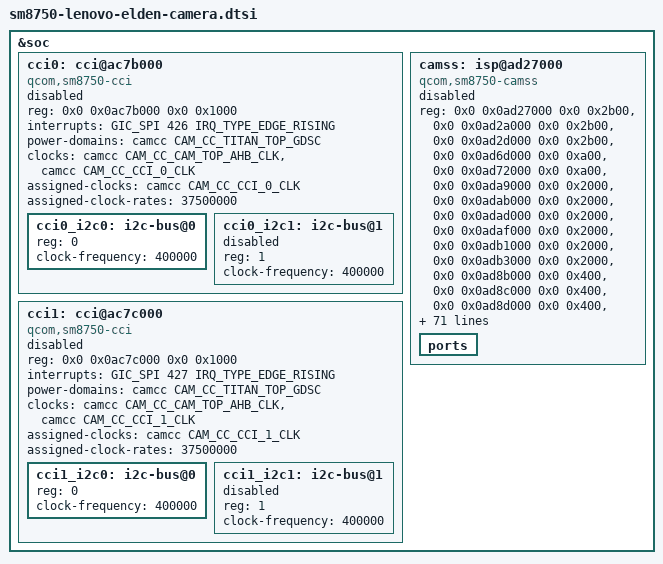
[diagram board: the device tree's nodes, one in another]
// SPDX-License-Identifier: BSD-3-Clause
/*
 * Copyright (c) 2024 Qualcomm Innovation Center, Inc. All rights reserved.
 *
 * CCI / CAMSS control nodes for the Lenovo Legion Y700 Gen4 (TB322FC).
 * Copied verbatim from sm8750.dtsi in h0cheung/tb322fc-linux-kernel,
 * commit 6f97250ead155fc3b980856323e99a4623dae73d, lines 3072-3309:
 *   cci0: cci@ac7b000, cci1: cci@ac7c000, camss: isp@ad27000.
 * Only leading indentation is normalized by one tab; all node contents are
 * unchanged. No other SoC delta is imported. These nodes supply the board
 * label references &camss, &cci0, &cci0_i2c0, &cci1 and &cci1_i2c0 used by
 * sm8750-lenovo-elden.dts; their clocks, interrupts and other phandles come
 * from the current upstream base. This file declares no driver and provides
 * no camera support.
 */

&soc {
	cci0: cci@ac7b000 {
		compatible = "qcom,sm8750-cci", "qcom,msm8996-cci";
		reg = <0x0 0x0ac7b000 0x0 0x1000>;
		interrupts = <GIC_SPI 426 IRQ_TYPE_EDGE_RISING>;
		power-domains = <&camcc CAM_CC_TITAN_TOP_GDSC>;
		clocks = <&camcc CAM_CC_CAM_TOP_AHB_CLK>,
			 <&camcc CAM_CC_CCI_0_CLK>;
		clock-names = "ahb", "cci";
		assigned-clocks = <&camcc CAM_CC_CCI_0_CLK>;
		assigned-clock-rates = <37500000>;
		status = "disabled";
		#address-cells = <1>;
		#size-cells = <0>;

		cci0_i2c0: i2c-bus@0 {
			reg = <0>;
			clock-frequency = <400000>;
			#address-cells = <1>;
			#size-cells = <0>;
		};

		cci0_i2c1: i2c-bus@1 {
			status = "disabled";
			reg = <1>;
			clock-frequency = <400000>;
			#address-cells = <1>;
			#size-cells = <0>;
		};
	};

	cci1: cci@ac7c000 {
		compatible = "qcom,sm8750-cci", "qcom,msm8996-cci";
		reg = <0x0 0x0ac7c000 0x0 0x1000>;
		interrupts = <GIC_SPI 427 IRQ_TYPE_EDGE_RISING>;
		power-domains = <&camcc CAM_CC_TITAN_TOP_GDSC>;
		clocks = <&camcc CAM_CC_CAM_TOP_AHB_CLK>,
			 <&camcc CAM_CC_CCI_1_CLK>;
		clock-names = "ahb", "cci";
		assigned-clocks = <&camcc CAM_CC_CCI_1_CLK>;
		assigned-clock-rates = <37500000>;
		status = "disabled";
		#address-cells = <1>;
		#size-cells = <0>;

		cci1_i2c0: i2c-bus@0 {
			reg = <0>;
			clock-frequency = <400000>;
			#address-cells = <1>;
			#size-cells = <0>;
		};

		cci1_i2c1: i2c-bus@1 {
			status = "disabled";
			reg = <1>;
			clock-frequency = <400000>;
			#address-cells = <1>;
			#size-cells = <0>;
		};
	};

	camss: isp@ad27000 {
		compatible = "qcom,sm8750-camss";

		reg = <0x0 0x0ad27000 0x0 0x2b00>,
		      <0x0 0x0ad2a000 0x0 0x2b00>,
		      <0x0 0x0ad2d000 0x0 0x2b00>,
		      <0x0 0x0ad6d000 0x0 0xa00>,
		      <0x0 0x0ad72000 0x0 0xa00>,
		      <0x0 0x0ada9000 0x0 0x2000>,
		      <0x0 0x0adab000 0x0 0x2000>,
		      <0x0 0x0adad000 0x0 0x2000>,
		      <0x0 0x0adaf000 0x0 0x2000>,
		      <0x0 0x0adb1000 0x0 0x2000>,
		      <0x0 0x0adb3000 0x0 0x2000>,
		      <0x0 0x0ad8b000 0x0 0x400>,
		      <0x0 0x0ad8c000 0x0 0x400>,
		      <0x0 0x0ad8d000 0x0 0x400>,
		      <0x0 0x0ac86000 0x0 0x10000>,
		      <0x0 0x0ac96000 0x0 0x10000>,
		      <0x0 0x0aca6000 0x0 0x10000>,
		      <0x0 0x0ad6e000 0x0 0x3000>,
		      <0x0 0x0ad73000 0x0 0x3000>;
		reg-names = "csid0",
			    "csid1",
			    "csid2",
			    "csid_lite0",
			    "csid_lite1",
			    "csiphy0",
			    "csiphy1",
			    "csiphy2",
			    "csiphy3",
			    "csiphy4",
			    "csiphy5",
			    "csitpg0",
			    "csitpg1",
			    "csitpg2",
			    "vfe0",
			    "vfe1",
			    "vfe2",
			    "vfe_lite0",
			    "vfe_lite1";

		clocks = <&camcc CAM_CC_CAMNOC_NRT_AXI_CLK>,
			 <&camcc CAM_CC_CAMNOC_RT_AXI_CLK>,
			 <&camcc CAM_CC_CAM_TOP_AHB_CLK>,
			 <&camcc CAM_CC_CAM_TOP_FAST_AHB_CLK>,
			 <&camcc CAM_CC_CAMNOC_RT_TFE_0_MAIN_CLK>,
			 <&camcc CAM_CC_CAMNOC_RT_TFE_1_MAIN_CLK>,
			 <&camcc CAM_CC_CAMNOC_RT_TFE_2_MAIN_CLK>,
			 <&camcc CAM_CC_CAMNOC_RT_IFE_LITE_CLK>,
			 <&camcc CAM_CC_CSID_CLK>,
			 <&camcc CAM_CC_CSID_CSIPHY_RX_CLK>,
			 <&camcc CAM_CC_CSIPHY0_CLK>,
			 <&camcc CAM_CC_CSI0PHYTIMER_CLK>,
			 <&camcc CAM_CC_CSIPHY1_CLK>,
			 <&camcc CAM_CC_CSI1PHYTIMER_CLK>,
			 <&camcc CAM_CC_CSIPHY2_CLK>,
			 <&camcc CAM_CC_CSI2PHYTIMER_CLK>,
			 <&camcc CAM_CC_CSIPHY3_CLK>,
			 <&camcc CAM_CC_CSI3PHYTIMER_CLK>,
			 <&camcc CAM_CC_CSIPHY4_CLK>,
			 <&camcc CAM_CC_CSI4PHYTIMER_CLK>,
			 <&camcc CAM_CC_CSIPHY5_CLK>,
			 <&camcc CAM_CC_CSI5PHYTIMER_CLK>,
			 <&gcc GCC_CAMERA_HF_AXI_CLK>,
			 <&gcc GCC_CAMERA_SF_AXI_CLK>,
			 <&camcc CAM_CC_TFE_0_MAIN_CLK>,
			 <&camcc CAM_CC_TFE_0_MAIN_FAST_AHB_CLK>,
			 <&camcc CAM_CC_TFE_1_MAIN_CLK>,
			 <&camcc CAM_CC_TFE_1_MAIN_FAST_AHB_CLK>,
			 <&camcc CAM_CC_TFE_2_MAIN_CLK>,
			 <&camcc CAM_CC_TFE_2_MAIN_FAST_AHB_CLK>,
			 <&camcc CAM_CC_IFE_LITE_CLK>,
			 <&camcc CAM_CC_IFE_LITE_AHB_CLK>,
			 <&camcc CAM_CC_IFE_LITE_CPHY_RX_CLK>,
			 <&camcc CAM_CC_IFE_LITE_CSID_CLK>,
			 <&camcc CAM_CC_QDSS_DEBUG_XO_CLK>;
		clock-names = "camnoc_nrt_axi",
			      "camnoc_rt_axi",
			      "cpas_ahb",
			      "cpas_fast_ahb",
			      "cpas_vfe0",
			      "cpas_vfe1",
			      "cpas_vfe2",
			      "cpas_vfe_lite",
			      "csid",
			      "csid_csiphy_rx",
			      "csiphy0",
			      "csiphy0_timer",
			      "csiphy1",
			      "csiphy1_timer",
			      "csiphy2",
			      "csiphy2_timer",
			      "csiphy3",
			      "csiphy3_timer",
			      "csiphy4",
			      "csiphy4_timer",
			      "csiphy5",
			      "csiphy5_timer",
			      "gcc_axi_hf",
			      "gcc_axi_sf",
			      "vfe0",
			      "vfe0_fast_ahb",
			      "vfe1",
			      "vfe1_fast_ahb",
			      "vfe2",
			      "vfe2_fast_ahb",
			      "vfe_lite",
			      "vfe_lite_ahb",
			      "vfe_lite_cphy_rx",
			      "vfe_lite_csid",
			      "qdss_debug_xo";

		interrupts = <GIC_SPI 601 IRQ_TYPE_EDGE_RISING>,
			     <GIC_SPI 603 IRQ_TYPE_EDGE_RISING>,
			     <GIC_SPI 431 IRQ_TYPE_EDGE_RISING>,
			     <GIC_SPI 605 IRQ_TYPE_EDGE_RISING>,
			     <GIC_SPI 376 IRQ_TYPE_EDGE_RISING>,
			     <GIC_SPI 477 IRQ_TYPE_EDGE_RISING>,
			     <GIC_SPI 478 IRQ_TYPE_EDGE_RISING>,
			     <GIC_SPI 479 IRQ_TYPE_EDGE_RISING>,
			     <GIC_SPI 448 IRQ_TYPE_EDGE_RISING>,
			     <GIC_SPI 122 IRQ_TYPE_EDGE_RISING>,
			     <GIC_SPI 89 IRQ_TYPE_EDGE_RISING>,
			     <GIC_SPI 433 IRQ_TYPE_EDGE_RISING>,
			     <GIC_SPI 436 IRQ_TYPE_EDGE_RISING>,
			     <GIC_SPI 457 IRQ_TYPE_EDGE_RISING>,
			     <GIC_SPI 606 IRQ_TYPE_EDGE_RISING>,
			     <GIC_SPI 377 IRQ_TYPE_EDGE_RISING>;
		interrupt-names = "csid0",
				  "csid1",
				  "csid2",
				  "csid_lite0",
				  "csid_lite1",
				  "csiphy0",
				  "csiphy1",
				  "csiphy2",
				  "csiphy3",
				  "csiphy4",
				  "csiphy5",
				  "vfe0",
				  "vfe1",
				  "vfe2",
				  "vfe_lite0",
				  "vfe_lite1";

		interconnects = <&gem_noc MASTER_APPSS_PROC QCOM_ICC_TAG_ACTIVE_ONLY
				 &config_noc SLAVE_CAMERA_CFG QCOM_ICC_TAG_ACTIVE_ONLY>,
				<&mmss_noc MASTER_CAMNOC_HF QCOM_ICC_TAG_ALWAYS
				 &mc_virt SLAVE_EBI1 QCOM_ICC_TAG_ALWAYS>,
				<&mmss_noc MASTER_CAMNOC_SF QCOM_ICC_TAG_ALWAYS
				 &mc_virt SLAVE_EBI1 QCOM_ICC_TAG_ALWAYS>,
				<&mmss_noc MASTER_CAMNOC_NRT_ICP_SF QCOM_ICC_TAG_ALWAYS
				 &mc_virt SLAVE_EBI1 QCOM_ICC_TAG_ALWAYS>;
		interconnect-names = "ahb",
				     "hf_mnoc",
				     "sf_mnoc",
				     "sf_icp_mnoc";

		iommus = <&apps_smmu 0x1c00 0x00>;

		power-domains = <&camcc CAM_CC_TFE_0_GDSC>,
				<&camcc CAM_CC_TFE_1_GDSC>,
				<&camcc CAM_CC_TFE_2_GDSC>,
				<&camcc CAM_CC_TITAN_TOP_GDSC>;
		power-domain-names = "ife0",
				     "ife1",
				     "ife2",
				     "top";

		dma-coherent;
		status = "disabled";

		ports {
			#address-cells = <1>;
			#size-cells = <0>;
		};
	};
};
